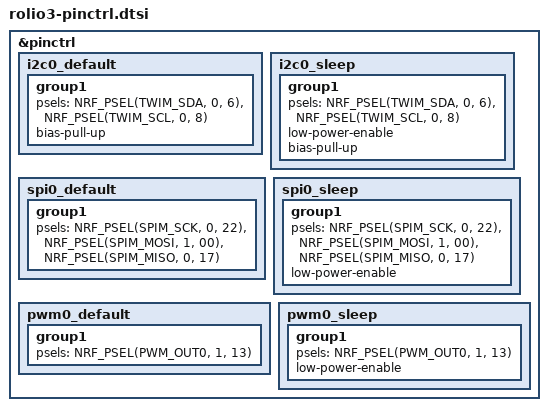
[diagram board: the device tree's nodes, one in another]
/*
 * Copyright (c) 2022 The ZMK Contributors
 * SPDX-License-Identifier: MIT
 */

&pinctrl {
    i2c0_default: i2c0_default {
        group1 {
            psels = <NRF_PSEL(TWIM_SDA, 0, 6)>,
                    <NRF_PSEL(TWIM_SCL, 0, 8)>;
            bias-pull-up;
        };
    };

    i2c0_sleep: i2c0_sleep {
        group1 {
            psels = <NRF_PSEL(TWIM_SDA, 0, 6)>,
                    <NRF_PSEL(TWIM_SCL, 0, 8)>;
            low-power-enable;
            bias-pull-up;
        };
    };

    spi0_default: spi0_default {
        group1 {
            psels = <NRF_PSEL(SPIM_SCK, 0, 22)>,
                <NRF_PSEL(SPIM_MOSI, 1, 00)>,
                <NRF_PSEL(SPIM_MISO, 0, 17)>;
        };
    };

    spi0_sleep: spi0_sleep {
        group1 {
            psels = <NRF_PSEL(SPIM_SCK, 0, 22)>,
                <NRF_PSEL(SPIM_MOSI, 1, 00)>,
                <NRF_PSEL(SPIM_MISO, 0, 17)>;
            low-power-enable;
        };
    };

    // Enable backlight controls
    pwm0_default: pwm0_default {
        group1 {
            // Use P0.08 for LED backlight
            psels = <NRF_PSEL(PWM_OUT0, 1, 13)>;
          };
    };

    pwm0_sleep: pwm0_sleep {
        group1 {
            // Use P0.08 for LED backlight
            psels = <NRF_PSEL(PWM_OUT0, 1, 13)>;
            low-power-enable;
          };
    };

};
